# M55M1 register map
File version: 1.0
Registers are 32-bit, read-write, reset 0x0 unless marked. A register's access mark holds for its fields unless they carry their own. Offsets are from the block's base; [hi:lo] are bit positions; {n}, {i} and the like mark numbered series; 'fields as' and 'values as' point back to an identical list.

## PSIO — PSIO Register Map
Base 0x40255000
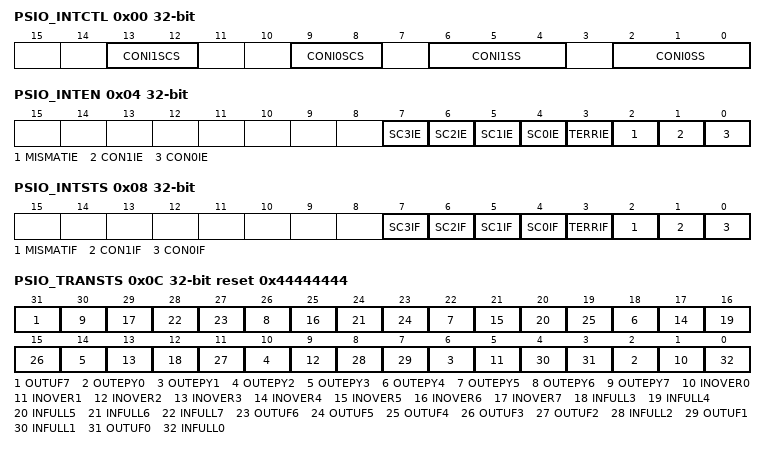
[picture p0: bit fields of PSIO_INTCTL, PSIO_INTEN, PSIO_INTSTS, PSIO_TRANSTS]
0x00 PSIO_INTCTL — PSIO Interrupt Control Register
  [13:12] CONI1SCS — Configurable Interrupt 1 Slot Controller Selection. Select Slot controller for interrupt 1.
    {v}=Slot controller {v} (v=0..3)
  [9:8] CONI0SCS — Configurable Interrupt 0 Slot Controller Selection. Select Slot controller for interrupt 0.
    {v}=Slot controller {v} (v=0..3)
  [6:4] CONI1SS — Configurable Interrupt 1 Slot Selection
    0=No use; {v}=SLOT{v-1} (v=1..8)
  [2:0] CONI0SS — Configurable Interrupt 0 Slot Selection
    0=No use; {v}=SLOT{v-1} (v=1..8)
0x04 PSIO_INTEN — PSIO Interrupt Enable Register
  [n+4] SC{n}IE (n=0..3) — Slot Controller {n} Done Interrupt Enable Bit. This field is used to enable Slot controller {n} finish interrupt.
    0=Slot controller {n} finish interrupt Disabled; 1=Slot controller {n} finish interrupt Enabled
  [3] TERRIE — Transfer Error Interrupt Enable Bit. This field is used to enable transfer error interrupt.
    0=Transfer error interrupt Disabled; 1=Transfer error interrupt Enabled
  [2] MISMATIE — Mismatch Interrupt Enable Bit. This field is used to enable mismatch interrupt.
    0=Mismatch interrupt Disabled; 1=Mismatch interrupt Enabled
  [1] CON1IE — Configurable Interrupt 1 Enable Bit. This field is used to enable selective interrupt 1.
    0=Selective interrupt 1 Disabled; 1=Selective interrupt 1 Enabled
  [0] CON0IE — Configurable Interrupt 0 Enable Bit. This field is used to enable selective interrupt 0.
    0=Selective interrupt 0 Disabled; 1=Selective interrupt 0 Enabled
0x08 PSIO_INTSTS — PSIO Interrupt Status Register
  [n+4] SC{n}IF (n=0..3) — Slot Controller {n} Counting Done Interrupt Status Flag. This field is used for slot controller {n} finish interrupt status flag. Note: This bit can be cleared by writing 1.
    0=Slot controller {n} done interrupt did not occur; 1=Slot controller {n} done interrupt occurred
  [3] TERRIF — Transfer Error Interrupt Status Flag. This field is used for transfer error interrupt status flag. The transfer error states is at PSIO_TRANSTS register which includes input data overflow flag INOVERn (PSIO_TRANSTS[29,25,21,17,13,9,5,1] and output data underflow flag OUTUFn (PSIO_TRANSTS[31,27,23,19,15,11,7,3]). Note 1: This field is the status flag of INOVER or OUTUFER. Note 2: This bit can only be cleared by writing 1 to coordinate transfer error.
    0=Transfer error interrupt did not occur; 1=Transfer error interrupt occurred
  [2] MISMATIF — Mismatch Interrupt Flag. This flag shows the amounts of data are not the same in each pins with PDMA enabled. If this situation happens, all slot controllers stop counting. Note 1: This flag is only effective on the pin with PDMA enabled. Note 2: This bit can be cleared by writing 1.
    0=Each pin with PDMA enabled receive or transfer data in the same rate; 1=Each pin with PDMA enabled receive or transfer data in different rate
  [1] CON1IF — Configurable Interrupt 1 Flag. The setting interrupt is trigger at the end of the check point of the pin. Note: This bit can be cleared by writing 1.
    0=Condition in PSIO_INTCTL is not triggered; 1=Condition in PSIO_INTCTL is triggered
  [0] CON0IF — Configurable Interrupt 0 Flag. The setting interrupt is trigger at the end of the check point of the pin. Note: This bit can be cleared by writing 1.
    values as CON1IF
0x0C PSIO_TRANSTS reset 0x44444444 — PSIO Transfer Status Register
  [31] OUTUF7 — Output Data Underflow Flag7. When PSIO is still output data but PSIOn_OUTDAT have not been ready, this flag will be set to 1. Note 1: When output data shortage happened, it will output 0. Note 2: When underflow happens, related slot controller will be stopped. Note 3: This bit can be cleared by configure 1 to it. Note 4: This bit will be cleared automatically when related slot controller started and pin enabled.
    0=The pin7 output data is not underflow; 1=The pin7 output data is underflow
  [4n+2] OUTEPY{n} ro (n=0..7) — Output Data Empty Flag{n} (Read Only)
    0=The pin{n} output data is full; 1=The pin{n} output data is empty
  [4n+1] INOVER{n} (n=0..7) — Input Data Overflow Flag{n}. Note 1: When input Overflow happened, it will keep the current data, and discard the upcoming data. Note 2: When overflow happens, related slot controller will be stopped. Note 3: This bit can be cleared by configure 1 to it. Note 4: This bit will be cleared automatically when related slot controller started and pin enabled.
    0=The pin{n} input data does not occur overflow; 1=The pin{n} input data occurs overflow
  [4n] INFULL{n} ro (n=3..7) — Input Data Full Flag{n} (Read Only). Note: This bit will be cleared automatically when related slot controller started and pin enabled.
    0=The pin{n} input data is empty; 1=The pin{n} input data is full
  [27] OUTUF6 — Output Data Underflow Flag6. When PSIO is still output data but PSIOn_OUTDAT have not been ready, this flag will be set to 1. Note 1: When output data shortage happened, it will output 0. Note 2: When underflow happens, related slot controller will be stopped. Note 3: This bit can be cleared by configure 1 to it. Note 4: This bit will be cleared automatically when related slot controller started and pin enabled.
    0=The pin6 output data is not underflow; 1=The pin6 output data is underflow
  [23] OUTUF5 — Output Data Underflow Flag5. When PSIO is still output data but PSIOn_OUTDAT have not been ready. This flag will be set to 1. Note 1: When output data shortage happened, it will output 0. Note 2: When underflow happens, related slot controller will be stopped. Note 3: This bit can be cleared by configure 1 to it. Note 4: This bit will be cleared automatically when related slot controller started and pin is enabled.
    0=The pin5 output data is not underflow; 1=The pin5 output data is underflow
  [19] OUTUF4 — Output Data Underflow Flag4. When PSIO is still output data but PSIOn_OUTDAT have not been ready. This flag will be set to 1. Note 1: When output data shortage happened, it will output 0. Note 2: When underflow happens, related slot controller will be stopped. Note 3: This bit can be cleared by configure 1 to it. Note 4: This bit will be cleared automatically when related slot controller started and pin enabled.
    0=The pin4 output data is not underflow; 1=The pin4 output data is underflow
  [15] OUTUF3 — Output Data Underflow Flag3. When PSIO is still output data but PSIOn_OUTDAT have not been ready. This flag will be set to 1. Note 1: When output data shortage happened, it will output 0. Note 2: When underflow happens, related slot controller will be stopped. Note 3: This bit can be cleared by configure 1 to it. Note 4: This bit will be cleared automatically when related slot controller started and pin enabled.
    0=The pin3 output data is not underflow; 1=The pin3 output data is underflow
  [11] OUTUF2 — Output Data Underflow Flag2. When PSIO is still output data but PSIOn_OUTDAT have not been ready. This flag will be set to 1. Note 1: When output data shortage happened, it will output 0. Note 2: When underflow happens, related slot controller will be stopped. Note 3: This bit can be cleared by configure 1 to it. Note 4: This bit will be cleared automatically when related slot controller started and pin enabled.
    values as OUTUF3
  [8] INFULL2 ro — Input Data Full Flag2 (Read Only). Note: This bit will be cleared automatically when related slot controller started and pin is enabled.
    0=The pin2 input data is empty; 1=The pin2 input data is full
  [7] OUTUF1 — Output Data Underflow Flag1. When PSIO is still output data but PSIOn_OUTDAT have not been ready. This flag will be set to 1. Note 1: When output data shortage happened, it will output 0. Note 2: When underflow happens, related slot controller will be stopped. Note 3: This bit can be cleared by configure 1 to it. Note 4: This bit will be cleared automatically when related slot controller started and pin enabled
    0=The pin1 output data is not underflow; 1=The pin1 output data is underflow
  [4] INFULL1 ro — Input Data Full Flag1 (Read Only). Note: This bit will be cleared automatically when related slot controller started and pin enabled.
    0=The pin1 input data is empty; 1=The pin1 input data is full
  [3] OUTUF0 — Output Data Underflow Flag0. When PSIO is still output data but PSIOn_OUTDAT have not been ready. This flag will be set to 1. Note 1: When output data shortage happened, it will output 0. Note 2: When underflow happens, related slot controller will be stopped. Note 3: This bit can be cleared by configure 1 to it. Note 4: This bit will be cleared automatically when related slot controller started and pin enabled.
    0=The pin0 output data is not underflow; 1=The pin0 output data is underflow
  [0] INFULL0 ro — Input Data Full Flag0 (Read Only). Note: This bit will be cleared automatically when related slot controller started and pin enabled.
    0=The pin0 input data is empty; 1=The pin0 input data is full
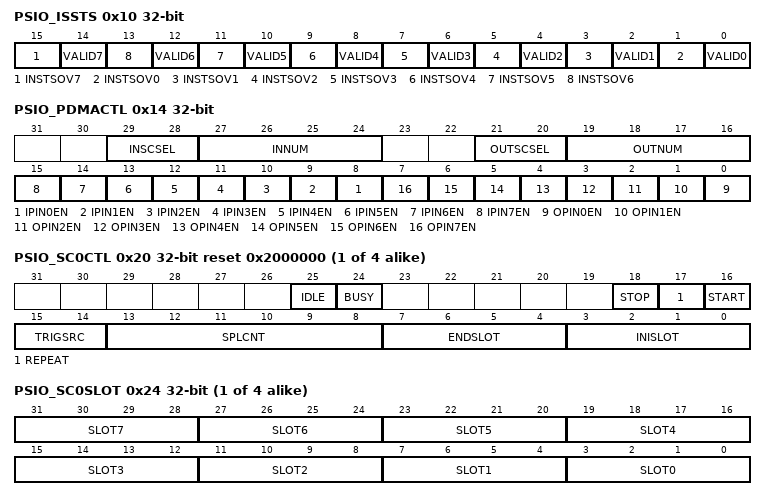
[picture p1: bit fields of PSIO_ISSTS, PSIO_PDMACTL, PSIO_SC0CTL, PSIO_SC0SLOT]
0x10 PSIO_ISSTS — PSIO Input Status State Register
  [15] INSTSOV7 — Input Status Overflow 7. Note: This overflow bit can be cleared by writing 1.
    0=The pin7 input status does not overflow; 1=The pin7 input status occur overflow
  [14] VALID7 — Input Status Valid 7. Note: This valid bit will be cleared automatically if PSIOn_INSTS is read.
    0=The pin7 input status is not ready; 1=The pin7 input status is ready
  [2n+1] INSTSOV{n} (n=0..6) — Input Status Overflow {n}. Note: This overflow bit can be cleared by writing 1.
    0=The pin {n} input status does not overflow; 1=The pin {n} input status occur overflow
  [12] VALID6 — Input Status Valid 6. Note: This valid bit will be cleared automatically if PSIOn_INSTS is read.
    0=The pin 6 input status is not ready; 1=The pin 6 input status is ready
  [10] VALID5 — Input Status Valid 5. Note: This valid bit will be cleared automatically if PSIOn_INSTS is read.
    0=The pin 5 input status is not ready; 1=The pin 5 input status is ready
  [8] VALID4 — Input Status Valid 4. Note: This valid bit will be cleared automatically if PSIOn_INSTS is read.
    0=The pin 4 input status is not ready; 1=The pin 4 input status is ready
  [6] VALID3 — Input Status Valid 3. Note: This valid bit will be cleared automatically if PSIOn_INSTS is read.
    0=The pin 3 input Status is not ready; 1=The pin 3 input Status is ready
  [4] VALID2 — Input Status Valid 2. Note: This valid bit will be cleared automatically if PSIOn_INSTS is read.
    0=The pin 2 input status is not ready; 1=The pin 2 input status is ready
  [2] VALID1 — Input Status Valid 1. Note: This valid bit will be cleared automatically if PSIOn_INSTS is read.
    0=The pin 1 input status is not ready; 1=The pin 1 input status is ready
  [0] VALID0 — Input Status Valid 0. Note: This valid bit will be cleared automatically if PSIOn_INSTS is read.
    0=The pin 0 input status is not ready; 1=The pin 0 input status is ready
0x14 PSIO_PDMACTL — PSIO PDMA Control Register
  [29:28] INSCSEL — PDMA Input Data Slot Controller Selection
    {v}=Slot controller {v} (v=0..3)
  [27:24] INNUM ro — PDMA Input Current Number (Read Only). This register shows the current pin number of input register read by PDMA.
    0=PDMA IDLE; {v}=Pin {v-1} (v=1..8); 9=PDMA WAIT
  [21:20] OUTSCSEL — PDMA Output Data Slot Controller Selection
    {v}=Slot controller {v} (v=0..3)
  [19:16] OUTNUM ro — PDMA Output Current Number (Read Only). This register shows the current pin number of output register write by PDMA.
    0=PDMA IDLE; 1=Pin 0; 2=Pin 1; 3=Pin 2; 4=P3; {v}=Pin {v-1} (v=5..8); 9=PDMA WAIT
  [n+8] IPIN{n}EN (n=0..7) — Input PDMA Pin{n} Enable Bit
    0=Pin{n} input PDMA function Disabled; 1=Pin{n} input PDMA function Enabled
  [n] OPIN{n}EN (n=0..7) — Output PDMA Pin{n} Enable Bit
    0=Pin{n} output PDMA function Disabled; 1=Pin{n} output PDMA function Enabled
0x18 PSIO_PODAT wo — PSIO PDMA Output Data Register
  [31:0] PDMAOUT — PDMA Output Data. This register is used for PSIO with PDMA single mode, and set PDMA with fixed address. When PSIO in PDMA mode, setting PDMA to write data to this register. The data in this register will be placed to corresponding PSIOn_OUTDAT register in order, when Output Data Empty Flag is 1 and PDMA mode enabled.
0x1C PSIO_PIDAT — PSIO PDMA Input Data Register
  [31:0] PDMAIN — PDMA Input Data. This register is used for PSIO with PDMA single mode, and set PDMA with fixed address. When PSIO in PDMA mode, setting PDMA to read data from this register. The data in this register will be updated from corresponding PSIOn_INDAT register in order, when Input Data Full Flag is 1 and PDMA mode enable.
{0x20+8i} PSIO_SC{i}CTL reset 0x2000000 (i=0..3) — PSIO Slot Controller n Control Register
  [25] IDLE — PSIO_SCn Idle Flag. Note 1: This bit will be cleared to 0 when slot controller starts to count automatically. Note 2: This bit will be set to 1 when configuring it 1 by software. Note 3: This bit is set to distinguish INTERVAL (PSIOn_GENCTL[5:4]) and INITIAL (PSIOn_GENCTL[3:2]).
    0=PSIO_SCn is not IDLE; 1=PSIO_SCn is IDLE
  [24] BUSY — PSIO_SCn Busy Flag. Note: This bit will be set to 1 when slot controller starts to count automatically and it will be cleared to 0 automatically when slot controller stops counting, too.
    0=PSIO_SCn is not busy; 1=PSIO_SCn is busy
  [18] STOP — PSIO_SCn Stop. Note: This bit is always read as 0.
    0=No use; 1=Stop PSIO_SCn
  [17] REPEAT — Whole Repeat Mode. Slot controller repeats counting forever. Note 1: If this bit is enabled with PDMA mode, slot controller will stop automatically when the PDMA finishes transferring number of data. Note 2: If PSIO receives stop instruction during repeat mode, it will stop only when the current loop is finished.
    0=Repeat mode Disabled; 1=Repeat mode Enabled
  [16] START — PSIO_SCn Start. Note: This bit is always read as 0.
    0=No use; 1=Start PSIO_SCn to count and active related PSIO_PIN
  [15:14] TRIGSRC — PSIO_SCn Trigger Source. Note 1: PSIO slot controller pin can only be triggered by related pins set from SCSEL(PSIOn_GENCTL[25:24]). Note 2: Configuring rising or falling signal trigger PSIO, the signal needs to hold for at least two PSIO_CLK for de-bounce or PSIO will not be triggered.
    0=Trigger by software; 1=Trigger PSIO_SCn when related PSIO_PIN occurred falling edge; 2=Trigger PSIO_SCn when related PSIO_PIN occurred rising edge; 3=Trigger PSIO_SCn when related PSIO_PIN occurred rising edge or falling edge
  [13:8] SPLCNT — Slot Period Loop Count. 000000 ~ 111110 is loop count. Note 1: If setting this register 111111 with PDMA mode and OUTPUT mode, it will stop automatically when PDMA is finished and output data in shift register is finished. Note 2: If setting this register 111111 with PDMA mode and INPUT mode, it will stop automatically when PDMA is finished. Note 3: If PSIO receives stop instruction during repeat mode, it will stop only when the current loop is finished.
    0=Slot period loop count function is disable; 1=Repeat selection loop once, which means total go through selected repeat slots 2 times; 63=Loop until stop PSIO slot controller
  [7:4] ENDSLOT — End Slot Period. The end slot of the repeat period.
    0=No use; {v}=SLOT{v-1} (v=1..8)
  [3:0] INISLOT — Initial Slot Period. The initial slot of the repeat period.
    0=No use; {v}=SLOT{v-1} (v=1..8)
{0x24+8i} PSIO_SC{i}SLOT (i=0..3) — PSIO Slot Controller n Slot Register
  [4n+3:4n] SLOT{n} (n=0..7) — PSIO Slot Controller Slot{n} Tick Count. 0 to 15. Note 1: Filling in all 0 to this field indicates to disable this slot. Note 2: The disabled slot should not be set between the enabled slots, or the order of enabled slot which is after the disabled slot will not be enabled. Note 3: The shortest slot length is 6 when I/O mode is switched from output mode to input mode.
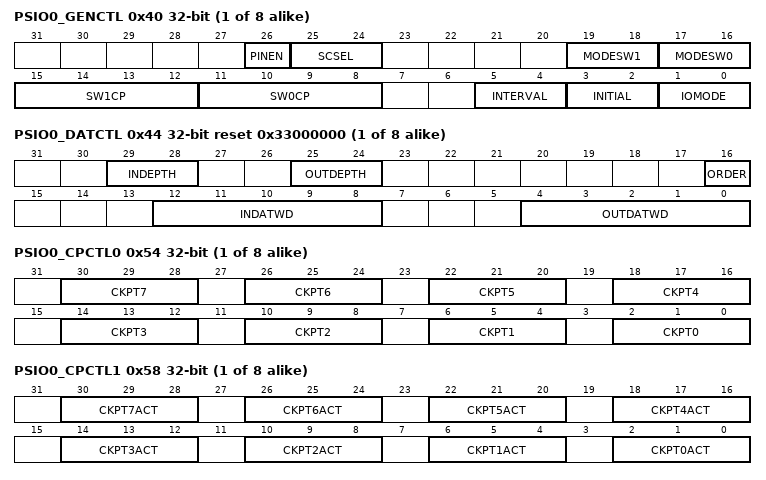
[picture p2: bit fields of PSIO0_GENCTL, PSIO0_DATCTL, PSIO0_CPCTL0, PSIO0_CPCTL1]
{0x40+0x20*i} PSIO{i}_GENCTL (i=0..7) — PSIOn General Control Register
  [26] PINEN — Pin Enable Bit
    0=Pin Disabled; 1=Pin Enabled
  [25:24] SCSEL — Slot Controller Selection. Select slot controller for check point.
    {v}=SLOT CONTROLLER{v} (v=0..3)
  [19:18] MODESW1 — Mode Switch1 Point. Mode at the switch1 point.
    0=Input mode; 1=Output mode; 2=Open-drain mode; 3=Quasi-bidirectional mode
  [17:16] MODESW0 — Mode Switch0 Point. Mode at the switch0 point.
    values as MODESW1
  [15:12] SW1CP — Switch1 Check Point
    0=No use; {v}=CHECK POINT {v-1} (v=1..8)
  [11:8] SW0CP — Switch0 Check Point
    0=No use; {v}=CHECK POINT {v-1} (v=1..8)
  [5:4] INTERVAL — Interval Output. The output of PSIO when slot controller stops counting and IDLE (PSIO_SCnCTL[25]) is 0. Note 1: Only when IOMODE is not input mode, then this register is effective. Note 2: This bit is effective only when IDLE(PSIO_SCnCTL[25]) is low.
    0=Low level; 1=High level; 2=Last output; 3=Toggle
  [3:2] INITIAL — Initial Output. The output state of PSIO when slot controller stops counting and IDLE (PSIO_SCnCTL[25]) is 1. Note 1: Only when IOMODE is not input mode, this register is effective. Note 2: This bit is effective only when IDLE(PSIO_SCnCTL[25]) is high.
    0=Low level; 1=High level; 2=Last output; 3=Toggle
  [1:0] IOMODE — I/O Mode. I/O mode state represent the I/O state when slot controller has not started counting or slot controller has started counting but has not cross the switch I/O mode check point. Note 1: When slot controller stops counting, it will switch to the current I/O mode setting. Note 2: When PSIO uses quasi-bidirectional mode or open-drain mode to trigger slot controller, the initial or interval output state needs to be set output high level, or the pin will not be triggered.
    values as MODESW1
{0x44+0x20*i} PSIO{i}_DATCTL reset 0x33000000 (i=0..7) — PSIOn Data Control Register
  [29:28] INDEPTH — Input Data Depth. Represent the data depth of the input buffer, when data width is larger than 16-bit, this setting can be ignored. When the data width is between 9-bit and 16 bit, Note 1: The input data depth impacts when the input data full flag and input data over flow flag is set to 1. Note 2: There is no difference of data depth no matter using software program data or PDMA program data.
    0=INDEPTH[0], the data depth is 1. INDEPTH, the data depth is 1; 1=INDEPTH[0], the data depth is 2. INDEPTH, the data depth is 2; 2=INDEPTH, the data depth is 3; 3=INDEPTH, the data depth is 4
  [25:24] OUTDEPTH — Output Data Depth. Represent the data depth of the output buffer, when data width is larger than 16-bit, this setting can be ignored. When the data width is between 9-bit and 16 bit, Note 1: The output data depth impacts when the output data empty flag and output under flow data flag is set to 1. Note 2: There is no difference of data depth no matter using software program data or PDMA program data.
    0=OUTDEPTH [0], the data depth is 1. OUTDEPTH, the data depth is 1; 1=OUTDEPTH [0], the data depth is 2. OUTDEPTH, the data depth is 2; 2=OUTDEPTH, the data depth is 3; 3=OUTDEPTH, the data depth is 4
  [16] ORDER — Order. The order of output data and input data.
    0=Data transfer start form LSB; 1=Data transfer start form MSB
  [12:8] INDATWD — Input Data Width. Indicate the data width of INPUT DATA register.
  [4:0] OUTDATWD — Output Data Width. Indicate the data width of OUTPUT DATA register.
{0x48+0x20*i} PSIO{i}_INSTS ro (i=0..7) — PSIOn Input Status Register
  [7:0] INSTS — Input Status. Status input buffer. This register can be read clear. Note: When the valid bit is set, the valid bits number of INSTS is equal to the number of check points from the previous time INSTS update to the current INSTS update.
{0x4C+0x20*i} PSIO{i}_INDAT ro (i=0..7) — PSIOn Input Data Register
  [31:0] INDAT — Input Data Buffer. This register can be read clear. Note: The input data sample time is according to the slot length. The sampling time is near 3/4 slot. When the slot length is 1, 2, 3, 4, 5, 6, 7, 8, 9, 10, 11, 12, 13, 14, 15, PSIO sample input data when the slot controller count to 1, 2, 2, 3, 4, 5, 5, 6, 6, 7, 7, 8, 8, 9, 9.
{0x50+0x20*i} PSIO{i}_OUTDAT wo (i=0..7) — PSIOn Output Data Register
  [31:0] OUTDAT — Output Data Buffer. This field is used to configure output data.
{0x54+0x20*i} PSIO{i}_CPCTL0 (i=0..7) — PSIOn Check Point Control Register 0
  [all] fields
    0=No use; {v}=SLOT{v-1} (v=1..8)
  [30:28] CKPT7 — Check Point 7. This field is used to link check point and slot controller slot. Note 1: If there are two check points that select the same SLOT, the pin will follow settings of the smaller check point number. Note 2: The correlated SLOT should be filled in order from SLOT0 to SLOT7, or the check point action will not be triggered.
  [4n+2:4n] CKPT{n} (n=0..6) — Check Point {n}. Note 1: If there are two check points that select the same SLOT, the pin will follow settings of the smaller check point number. Note 2: The correlated SLOT should be filled in order from SLOT0 to SLOT7, or the check point action will not be triggered.
{0x58+0x20*i} PSIO{i}_CPCTL1 (i=0..7) — PSIOn Check Point Control Register 1
  [all] fields
    0=Output level low; 1=Output level high; 2=Output from data buffer; 3=Output toggle; 4=Input data buffer; 5=Input status; 6=Input status record and update
  [4n+2:4n] CKPT{n}ACT (n=0..7) — Check Point {n} Action. Select check point action at check point{n}. Note: Pin action must meet the correlated I/O mode (PSIOn_GENCTL[1:0]).
